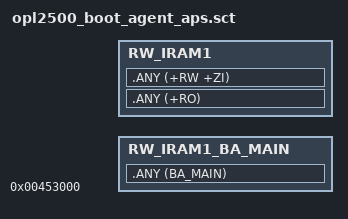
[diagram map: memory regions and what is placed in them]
#! armcc -E
; *************************************************************
; *** Scatter-Loading Description File generated by uVision ***
; *************************************************************
#define APS_CACHE_START             0x00454000
;Using last part of HEAP to avoid overlap to APS firmware (cache RAM is released for firmware)
#define BOOT_AGENT_REGION_LENGTH    0x1000
#define BOOT_AGENT_REGION_START     APS_CACHE_START - BOOT_AGENT_REGION_LENGTH


LR_IROM1 BOOT_AGENT_REGION_START BOOT_AGENT_REGION_LENGTH  {    ; load region size_region
    RW_IRAM1_BA_MAIN +0
    {
        .ANY (BA_MAIN)
    }
    RW_IRAM1 +0 
    {
       .ANY (+RO)
       .ANY (+RW +ZI)
    }
}
ScatterAssert(ImageLimit(RW_IRAM1) <= APS_CACHE_START)
